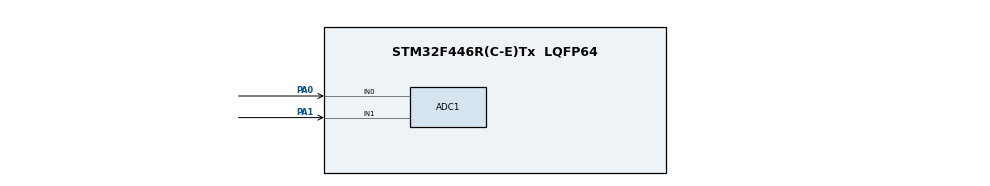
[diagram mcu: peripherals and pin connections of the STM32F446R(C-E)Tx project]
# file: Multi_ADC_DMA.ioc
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ADC1.Channel-0\#ChannelRegularConversion=ADC_CHANNEL_0
ADC1.Channel-1\#ChannelRegularConversion=ADC_CHANNEL_TEMPSENSOR
ADC1.Channel-2\#ChannelRegularConversion=ADC_CHANNEL_VREFINT
ADC1.Channel-3\#ChannelRegularConversion=ADC_CHANNEL_1
ADC1.EOCSelection=ADC_EOC_SEQ_CONV
ADC1.ExternalTrigConv=ADC_EXTERNALTRIGCONV_T2_TRGO
ADC1.NbrOfConversion=4
ADC1.NbrOfConversionFlag=1
ADC1.Rank-0\#ChannelRegularConversion=1
ADC1.Rank-1\#ChannelRegularConversion=2
ADC1.Rank-2\#ChannelRegularConversion=3
ADC1.Rank-3\#ChannelRegularConversion=4
ADC1.SamplingTime-0\#ChannelRegularConversion=ADC_SAMPLETIME_84CYCLES
ADC1.SamplingTime-1\#ChannelRegularConversion=ADC_SAMPLETIME_84CYCLES
ADC1.SamplingTime-2\#ChannelRegularConversion=ADC_SAMPLETIME_15CYCLES
ADC1.SamplingTime-3\#ChannelRegularConversion=ADC_SAMPLETIME_84CYCLES
ADC1.master=1
Dma.ADC1.0.Direction=DMA_PERIPH_TO_MEMORY
Dma.ADC1.0.FIFOMode=DMA_FIFOMODE_DISABLE
Dma.ADC1.0.Instance=DMA2_Stream0
Dma.ADC1.0.MemDataAlignment=DMA_MDATAALIGN_WORD
Dma.ADC1.0.MemInc=DMA_MINC_ENABLE
Dma.ADC1.0.Mode=DMA_NORMAL
Dma.ADC1.0.PeriphDataAlignment=DMA_PDATAALIGN_WORD
Dma.ADC1.0.PeriphInc=DMA_PINC_DISABLE
Dma.ADC1.0.Priority=DMA_PRIORITY_LOW
Dma.Request0=ADC1
Mcu.Family=STM32F4
Mcu.Name=STM32F446R(C-E)Tx
Mcu.Package=LQFP64
NVIC.DMA2_Stream0_IRQn=true\:0\:0\:false\:false\:true\:false\:true\:true
NVIC.PriorityGroup=NVIC_PRIORITYGROUP_4
PA0-WKUP.Signal=ADCx_IN0
PA1.Signal=ADCx_IN1
PA13.Mode=Serial_Wire
PA13.Signal=SYS_JTMS-SWDIO
PA14.Mode=Serial_Wire
PA14.Signal=SYS_JTCK-SWCLK
PC13.Mode=SYS_WakeUp1
PC13.Signal=SYS_WKUP1
ProjectManager.HeapSize=0x200
ProjectManager.StackSize=0x400
ProjectManager.TargetToolchain=STM32CubeIDE
RCC.CortexFreq_Value=16000000
RCC.USBFreq_Value=96000000
RCC.VCOOutputFreq_Value=192000000
SH.ADCx_IN0.0=ADC1_IN0,IN0
SH.ADCx_IN1.0=ADC1_IN1,IN1
TIM2.Period=1000-1
TIM2.Prescaler=16000-1
TIM2.TIM_MasterOutputTrigger=TIM_TRGO_UPDATE
TIM2.TIM_MasterSlaveMode=TIM_MASTERSLAVEMODE_ENABLE
VP_ADC1_TempSens_Input.Mode=IN-TempSens
VP_ADC1_Vref_Input.Mode=IN-Vrefint
VP_TIM2_VS_ClockSourceINT.Mode=Internal
board=custom

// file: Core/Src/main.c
/* USER CODE BEGIN Header */
/**
  ******************************************************************************
  * @file           : main.c
  * @brief          : Main program body
  ******************************************************************************
  * @attention
  *
  * Copyright (c) 2024 STMicroelectronics.
  * All rights reserved.
  *
  * This software is licensed under terms that can be found in the LICENSE file
  * in the root directory of this software component.
  * If no LICENSE file comes with this software, it is provided AS-IS.
  *
  ******************************************************************************
  */
/* USER CODE END Header */
#include "main.h"

/* USER CODE BEGIN PD */

#define ADC_BUF_SIZE  4
#define __VREFANALOG_VOLTAGE__ 3300 // millivolt

/* USER CODE END PD */

ADC_HandleTypeDef hadc1;
DMA_HandleTypeDef hdma_adc1;

TIM_HandleTypeDef htim2;

/* USER CODE BEGIN PV */

uint32_t adc_buffer[ADC_BUF_SIZE];
uint8_t adc_ready = 0;

uint32_t ch0_mv;
uint32_t ch1_mv;
uint32_t intTempC;
uint32_t vref_int_mv;

/* USER CODE END PV */

void SystemClock_Config(void);
static void MX_GPIO_Init(void);
static void MX_DMA_Init(void);
static void MX_ADC1_Init(void);
static void MX_TIM2_Init(void);
/* USER CODE BEGIN PFP */

uint32_t CalculateVoltage(uint32_t Vref, uint32_t AdcValue, uint32_t Resolution);
int32_t CalculateTemperature(uint32_t Vref, uint32_t AdcValue, uint32_t Resolution);

/* USER CODE END PFP */

int main(void)
{

  /* MCU Configuration--------------------------------------------------------*/

  /* Reset of all peripherals, Initializes the Flash interface and the Systick. */
  HAL_Init();

  /* Configure the system clock */
  SystemClock_Config();

  /* Initialize all configured peripherals */
  MX_GPIO_Init();
  MX_DMA_Init();
  MX_ADC1_Init();
  MX_TIM2_Init();
  /* USER CODE BEGIN 2 */

  HAL_TIM_Base_Start(&htim2);

  /* USER CODE END 2 */

  /* Infinite loop */
  while (1)
  {

    /* USER CODE BEGIN 3 */
	  while(adc_ready !=1)
	  {

	  }
	  adc_ready = 0;

	  ch0_mv = CalculateVoltage(__VREFANALOG_VOLTAGE__,adc_buffer[0],ADC_RESOLUTION12b);
	  intTempC = CalculateTemperature(__VREFANALOG_VOLTAGE__,adc_buffer[1],ADC_RESOLUTION12b);
	  vref_int_mv = CalculateVoltage(__VREFANALOG_VOLTAGE__,adc_buffer[2],ADC_RESOLUTION12b);
	  ch1_mv = CalculateVoltage(__VREFANALOG_VOLTAGE__,adc_buffer[3],ADC_RESOLUTION12b);

	  HAL_ADC_Start_DMA(&hadc1, adc_buffer, ADC_BUF_SIZE);
  }
  /* USER CODE END 3 */
}

void SystemClock_Config(void)
{
  RCC_OscInitTypeDef RCC_OscInitStruct = {0};
  RCC_ClkInitTypeDef RCC_ClkInitStruct = {0};

  /** Configure the main internal regulator output voltage
  */
  __HAL_RCC_PWR_CLK_ENABLE();
  __HAL_PWR_VOLTAGESCALING_CONFIG(PWR_REGULATOR_VOLTAGE_SCALE3);

  /** Initializes the RCC Oscillators according to the specified parameters
  * in the RCC_OscInitTypeDef structure.
  */
  RCC_OscInitStruct.OscillatorType = RCC_OSCILLATORTYPE_HSI;
  RCC_OscInitStruct.HSIState = RCC_HSI_ON;
  RCC_OscInitStruct.HSICalibrationValue = RCC_HSICALIBRATION_DEFAULT;
  RCC_OscInitStruct.PLL.PLLState = RCC_PLL_NONE;
  if (HAL_RCC_OscConfig(&RCC_OscInitStruct) != HAL_OK)
  {
    Error_Handler();
  }

  /** Initializes the CPU, AHB and APB buses clocks
  */
  RCC_ClkInitStruct.ClockType = RCC_CLOCKTYPE_HCLK|RCC_CLOCKTYPE_SYSCLK
                              |RCC_CLOCKTYPE_PCLK1|RCC_CLOCKTYPE_PCLK2;
  RCC_ClkInitStruct.SYSCLKSource = RCC_SYSCLKSOURCE_HSI;
  RCC_ClkInitStruct.AHBCLKDivider = RCC_SYSCLK_DIV1;
  RCC_ClkInitStruct.APB1CLKDivider = RCC_HCLK_DIV1;
  RCC_ClkInitStruct.APB2CLKDivider = RCC_HCLK_DIV1;

  if (HAL_RCC_ClockConfig(&RCC_ClkInitStruct, FLASH_LATENCY_0) != HAL_OK)
  {
    Error_Handler();
  }
}

static void MX_ADC1_Init(void)
{

  ADC_ChannelConfTypeDef sConfig = {0};

  /** Configure the global features of the ADC (Clock, Resolution, Data Alignment and number of conversion)
  */
  hadc1.Instance = ADC1;
  hadc1.Init.ClockPrescaler = ADC_CLOCK_SYNC_PCLK_DIV2;
  hadc1.Init.Resolution = ADC_RESOLUTION_12B;
  hadc1.Init.ScanConvMode = ENABLE;
  hadc1.Init.ContinuousConvMode = DISABLE;
  hadc1.Init.DiscontinuousConvMode = DISABLE;
  hadc1.Init.ExternalTrigConvEdge = ADC_EXTERNALTRIGCONVEDGE_RISING;
  hadc1.Init.ExternalTrigConv = ADC_EXTERNALTRIGCONV_T2_TRGO;
  hadc1.Init.DataAlign = ADC_DATAALIGN_RIGHT;
  hadc1.Init.NbrOfConversion = 4;
  hadc1.Init.DMAContinuousRequests = DISABLE;
  hadc1.Init.EOCSelection = ADC_EOC_SEQ_CONV;
  if (HAL_ADC_Init(&hadc1) != HAL_OK)
  {
    Error_Handler();
  }

  /** Configure for the selected ADC regular channel its corresponding rank in the sequencer and its sample time.
  */
  sConfig.Channel = ADC_CHANNEL_0;
  sConfig.Rank = 1;
  sConfig.SamplingTime = ADC_SAMPLETIME_84CYCLES;
  if (HAL_ADC_ConfigChannel(&hadc1, &sConfig) != HAL_OK)
  {
    Error_Handler();
  }

  /** Configure for the selected ADC regular channel its corresponding rank in the sequencer and its sample time.
  */
  sConfig.Channel = ADC_CHANNEL_TEMPSENSOR;
  sConfig.Rank = 2;
  if (HAL_ADC_ConfigChannel(&hadc1, &sConfig) != HAL_OK)
  {
    Error_Handler();
  }

  /** Configure for the selected ADC regular channel its corresponding rank in the sequencer and its sample time.
  */
  sConfig.Channel = ADC_CHANNEL_VREFINT;
  sConfig.Rank = 3;
  sConfig.SamplingTime = ADC_SAMPLETIME_15CYCLES;
  if (HAL_ADC_ConfigChannel(&hadc1, &sConfig) != HAL_OK)
  {
    Error_Handler();
  }

  /** Configure for the selected ADC regular channel its corresponding rank in the sequencer and its sample time.
  */
  sConfig.Channel = ADC_CHANNEL_1;
  sConfig.Rank = 4;
  sConfig.SamplingTime = ADC_SAMPLETIME_84CYCLES;
  if (HAL_ADC_ConfigChannel(&hadc1, &sConfig) != HAL_OK)
  {
    Error_Handler();
  }

}

static void MX_TIM2_Init(void)
{

  TIM_ClockConfigTypeDef sClockSourceConfig = {0};
  TIM_MasterConfigTypeDef sMasterConfig = {0};

  htim2.Instance = TIM2;
  htim2.Init.Prescaler = 16000-1;
  htim2.Init.CounterMode = TIM_COUNTERMODE_UP;
  htim2.Init.Period = 1000-1;
  htim2.Init.ClockDivision = TIM_CLOCKDIVISION_DIV1;
  htim2.Init.AutoReloadPreload = TIM_AUTORELOAD_PRELOAD_DISABLE;
  if (HAL_TIM_Base_Init(&htim2) != HAL_OK)
  {
    Error_Handler();
  }
  sClockSourceConfig.ClockSource = TIM_CLOCKSOURCE_INTERNAL;
  if (HAL_TIM_ConfigClockSource(&htim2, &sClockSourceConfig) != HAL_OK)
  {
    Error_Handler();
  }
  sMasterConfig.MasterOutputTrigger = TIM_TRGO_UPDATE;
  sMasterConfig.MasterSlaveMode = TIM_MASTERSLAVEMODE_ENABLE;
  if (HAL_TIMEx_MasterConfigSynchronization(&htim2, &sMasterConfig) != HAL_OK)
  {
    Error_Handler();
  }

}

static void MX_DMA_Init(void)
{

  /* DMA controller clock enable */
  __HAL_RCC_DMA2_CLK_ENABLE();

  /* DMA interrupt init */
  /* DMA2_Stream0_IRQn interrupt configuration */
  HAL_NVIC_SetPriority(DMA2_Stream0_IRQn, 0, 0);
  HAL_NVIC_EnableIRQ(DMA2_Stream0_IRQn);

}

static void MX_GPIO_Init(void)
{

  /* GPIO Ports Clock Enable */
  __HAL_RCC_GPIOC_CLK_ENABLE();
  __HAL_RCC_GPIOA_CLK_ENABLE();

}

/* USER CODE BEGIN 4 */

void HAL_ADC_ConvCpltCallback(ADC_HandleTypeDef *hadc)
{
  /* Prevent unused argument(s) compilation warning */
  UNUSED(hadc);
  adc_ready = 1;
  HAL_ADC_Stop_DMA(&hadc1);
  /* NOTE : This function Should not be modified, when the callback is needed,
            the HAL_ADC_ConvCpltCallback could be implemented in the user file
   */
}

// Function to calculate the voltage (in millivolts) from ADC data

uint32_t CalculateVoltage(uint32_t Vref, uint32_t AdcValue, uint32_t Resolution) {
    return (AdcValue * Vref) / ((1 << Resolution) - 1);
}

// Function to calculate the temperature (in degrees Celsius) from ADC data

int32_t CalculateTemperature(uint32_t Vref, uint32_t AdcValue, uint32_t Resolution) {
    // Retrieve calibration values from system memory
    uint16_t *TEMP30_CAL_ADDR = (uint16_t*)0x1FFF7A2C; // Address for temperature sensor calibration value at 30°C
    uint16_t *TEMP110_CAL_ADDR = (uint16_t*)0x1FFF7A2E; // Address for temperature sensor calibration value at 110°C

    // Calculate temperature
    int32_t temperature = (((int32_t)AdcValue * Vref / 3300) - (int32_t)(*TEMP30_CAL_ADDR));
    temperature = temperature * (int32_t)(110 - 30);
    temperature = temperature / (int32_t)(*TEMP110_CAL_ADDR - *TEMP30_CAL_ADDR);
    temperature = temperature + 30;

    return temperature;
}

/* USER CODE END 4 */

void Error_Handler(void)
{
  __disable_irq();
  while (1)
  {
  }
}
